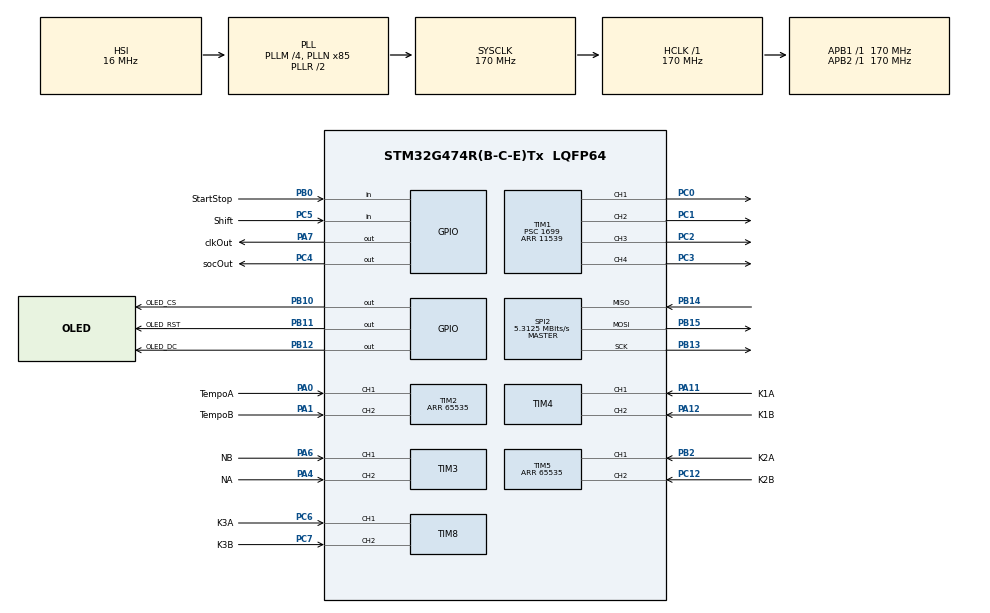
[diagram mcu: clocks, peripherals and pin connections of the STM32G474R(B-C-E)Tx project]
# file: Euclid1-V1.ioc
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Mcu.Family=STM32G4
Mcu.Name=STM32G474R(B-C-E)Tx
Mcu.Package=LQFP64
NUCLEO-G474RE.VCP=true
NVIC.PriorityGroup=NVIC_PRIORITYGROUP_4
NVIC.TIM1_TRG_COM_TIM17_IRQn=true\:1\:0\:true\:false\:true\:true\:true\:true
NVIC.TIM1_UP_TIM16_IRQn=true\:0\:0\:false\:false\:true\:true\:true\:true
PA0.GPIO_Label=TempoA
PA0.GPIO_PuPd=GPIO_PULLUP
PA0.Signal=S_TIM2_CH1
PA1.GPIO_Label=TempoB
PA1.GPIO_PuPd=GPIO_PULLUP
PA1.Signal=S_TIM2_CH2
PA11.GPIO_Label=K1A
PA11.GPIO_PuPd=GPIO_PULLUP
PA11.Signal=S_TIM4_CH1
PA12.GPIO_Label=K1B
PA12.GPIO_PuPd=GPIO_PULLUP
PA12.Signal=S_TIM4_CH2
PA13.GPIO_Label=T_SWDIO
PA13.Mode=Serial_Wire
PA13.Signal=SYS_JTMS-SWDIO
PA14.GPIO_Label=T_SWCLK
PA14.Mode=Serial_Wire
PA14.Signal=SYS_JTCK-SWCLK
PA2.Signal=LPUART1_TX
PA3.Signal=LPUART1_RX
PA4.GPIO_Label=NA
PA4.GPIO_PuPd=GPIO_PULLUP
PA4.Signal=S_TIM3_CH2
PA6.GPIO_Label=NB
PA6.GPIO_PuPd=GPIO_PULLUP
PA6.Signal=S_TIM3_CH1
PA7.GPIO_Label=clkOut
PA7.Signal=GPIO_Output
PB0.GPIO_Label=StartStop
PB0.GPIO_PuPd=GPIO_PULLUP
PB0.Signal=GPIO_Input
PB10.GPIO_Label=OLED_CS
PB10.PinState=GPIO_PIN_SET
PB10.Signal=GPIO_Output
PB11.GPIO_Label=OLED_RST
PB11.Signal=GPIO_Output
PB12.GPIO_Label=OLED_DC
PB12.Signal=GPIO_Output
PB13.Mode=Full_Duplex_Master
PB13.Signal=SPI2_SCK
PB14.Mode=Full_Duplex_Master
PB14.Signal=SPI2_MISO
PB15.Mode=Full_Duplex_Master
PB15.Signal=SPI2_MOSI
PB2.GPIO_Label=K2A
PB2.GPIO_PuPd=GPIO_PULLUP
PB2.Signal=S_TIM5_CH1
PB3.GPIO_Label=T_SWO
PB3.Signal=SYS_JTDO-SWO
PC0.Signal=S_TIM1_CH1
PC1.Signal=S_TIM1_CH2
PC12.GPIO_Label=K2B
PC12.GPIO_PuPd=GPIO_PULLUP
PC12.Signal=S_TIM5_CH2
PC14-OSC32_IN.GPIO_Label=RCC_OSC32_IN
PC14-OSC32_IN.Signal=RCC_OSC32_IN
PC15-OSC32_OUT.GPIO_Label=RCC_OSC32_OUT
PC15-OSC32_OUT.Signal=RCC_OSC32_OUT
PC2.Signal=S_TIM1_CH3
PC3.Signal=S_TIM1_CH4
PC4.GPIO_Label=socOut
PC4.GPIO_PuPd=GPIO_NOPULL
PC4.Signal=GPIO_Output
PC5.GPIO_Label=Shift
PC5.GPIO_PuPd=GPIO_PULLUP
PC5.Signal=GPIO_Input
PC6.GPIO_Label=K3A
PC6.GPIO_PuPd=GPIO_PULLUP
PC6.Signal=S_TIM8_CH1
PC7.GPIO_Label=K3B
PC7.GPIO_PuPd=GPIO_PULLUP
PC7.Signal=S_TIM8_CH2
PF0-OSC_IN.GPIO_Label=RCC_OSC_IN
PF0-OSC_IN.Signal=RCC_OSC_IN
PF1-OSC_OUT.GPIO_Label=RCC_OSC_OUT
PF1-OSC_OUT.Signal=RCC_OSC_OUT
ProjectManager.HeapSize=0x200
ProjectManager.StackSize=0x400
ProjectManager.TargetToolchain=STM32CubeIDE
RCC.ADC12Freq_Value=170000000
RCC.ADC345Freq_Value=170000000
RCC.AHBFreq_Value=170000000
RCC.APB1Freq_Value=170000000
RCC.APB1TimFreq_Value=170000000
RCC.APB2Freq_Value=170000000
RCC.APB2TimFreq_Value=170000000
RCC.CortexFreq_Value=170000000
RCC.EXTERNAL_CLOCK_VALUE=12288000
RCC.HCLKFreq_Value=170000000
RCC.HSE_VALUE=24000000
RCC.HSI48_VALUE=48000000
RCC.HSI_VALUE=16000000
RCC.LSE_VALUE=32768
RCC.PLLM=RCC_PLLM_DIV4
RCC.PLLN=85
RCC.RTCClockSelection=RCC_RTCCLKSOURCE_LSE
RCC.SYSCLKFreq_VALUE=170000000
RCC.SYSCLKSource=RCC_SYSCLKSOURCE_PLLCLK
RCC.USBFreq_Value=170000000
RCC.VCOOutputFreq_Value=340000000
SH.S_TIM1_CH1.0=TIM1_CH1,PWM Generation1 CH1
SH.S_TIM1_CH2.0=TIM1_CH2,PWM Generation2 CH2
SH.S_TIM1_CH3.0=TIM1_CH3,PWM Generation3 CH3
SH.S_TIM1_CH4.0=TIM1_CH4,PWM Generation4 CH4
SH.S_TIM2_CH1.0=TIM2_CH1,Encoder_Interface
SH.S_TIM2_CH2.0=TIM2_CH2,Encoder_Interface
SH.S_TIM3_CH1.0=TIM3_CH1,Encoder_Interface
SH.S_TIM3_CH2.0=TIM3_CH2,Encoder_Interface
SH.S_TIM4_CH1.0=TIM4_CH1,Encoder_Interface
SH.S_TIM4_CH2.0=TIM4_CH2,Encoder_Interface
SH.S_TIM5_CH1.0=TIM5_CH1,Encoder_Interface
SH.S_TIM5_CH2.0=TIM5_CH2,Encoder_Interface
SH.S_TIM8_CH1.0=TIM8_CH1,Encoder_Interface
SH.S_TIM8_CH2.0=TIM8_CH2,Encoder_Interface
SPI2.BaudRatePrescaler=SPI_BAUDRATEPRESCALER_32
SPI2.CalculateBaudRate=5.3125 MBits/s
SPI2.DataSize=SPI_DATASIZE_8BIT
SPI2.Direction=SPI_DIRECTION_2LINES
SPI2.Mode=SPI_MODE_MASTER
SPI2.VirtualType=VM_MASTER
TIM1.AutoReloadPreload=TIM_AUTORELOAD_PRELOAD_ENABLE
TIM1.Channel-PWM\ Generation1\ CH1=TIM_CHANNEL_1
TIM1.Channel-PWM\ Generation2\ CH2=TIM_CHANNEL_2
TIM1.Channel-PWM\ Generation3\ CH3=TIM_CHANNEL_3
TIM1.Channel-PWM\ Generation4\ CH4=TIM_CHANNEL_4
TIM1.PeriodNoDither=11539
TIM1.Prescaler=1699
TIM1.TIM_MasterOutputTrigger=TIM_TRGO_UPDATE
TIM17.PeriodNoDither=11539
TIM17.Prescaler=1699
TIM2.EncoderMode=TIM_ENCODERMODE_TI12
TIM2.IC1Filter=8
TIM2.IC2Filter=8
TIM2.PeriodNoDither=65535
TIM3.EncoderMode=TIM_ENCODERMODE_TI12
TIM3.IC1Filter=8
TIM3.IC2Filter=8
TIM4.EncoderMode=TIM_ENCODERMODE_TI12
TIM4.IC1Filter=8
TIM4.IC2Filter=8
TIM5.EncoderMode=TIM_ENCODERMODE_TI12
TIM5.IC1Filter=8
TIM5.IC2Filter=8
TIM5.PeriodNoDither=65535
TIM8.EncoderMode=TIM_ENCODERMODE_TI12
TIM8.IC1Filter=8
TIM8.IC2Filter=8
VP_NUCLEO-G474RE_VS_BSP_COMMON.Mode=COMMON
VP_SYS_VS_DBSignals.Mode=DisableDeadBatterySignals
VP_TIM17_VS_ClockSourceINT.Mode=Enable_Timer
VP_TIM17_VS_OPM.Mode=OPM_bit
board=NUCLEO-G474RE

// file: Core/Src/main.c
/* USER CODE BEGIN Header */
/**
  ******************************************************************************
  * @file           : main.c
  * @brief          : Main program body
  ******************************************************************************
  * @attention
  *
  * Copyright (c) 2026 STMicroelectronics.
  * All rights reserved.
  *
  * This software is licensed under terms that can be found in the LICENSE file
  * in the root directory of this software component.
  * If no LICENSE file comes with this software, it is provided AS-IS.
  *
  ******************************************************************************
  */
/* USER CODE END Header */
#include "main.h"

/* USER CODE BEGIN Includes */
#include "app.h"
/* USER CODE END Includes */

COM_InitTypeDef BspCOMInit;
SPI_HandleTypeDef hspi2;

TIM_HandleTypeDef htim1;
TIM_HandleTypeDef htim2;
TIM_HandleTypeDef htim3;
TIM_HandleTypeDef htim4;
TIM_HandleTypeDef htim5;
TIM_HandleTypeDef htim8;
TIM_HandleTypeDef htim17;

void SystemClock_Config(void);
static void MX_GPIO_Init(void);
static void MX_TIM1_Init(void);
static void MX_TIM2_Init(void);
static void MX_TIM3_Init(void);
static void MX_TIM4_Init(void);
static void MX_TIM5_Init(void);
static void MX_TIM8_Init(void);
static void MX_TIM17_Init(void);
static void MX_SPI2_Init(void);

int main(void)
{

  /* MCU Configuration--------------------------------------------------------*/

  /* Reset of all peripherals, Initializes the Flash interface and the Systick. */
  HAL_Init();

  /* Configure the system clock */
  SystemClock_Config();

  /* Initialize all configured peripherals */
  MX_GPIO_Init();
  MX_TIM1_Init();
  MX_TIM2_Init();
  MX_TIM3_Init();
  MX_TIM4_Init();
  MX_TIM5_Init();
  MX_TIM8_Init();
  MX_TIM17_Init();
  MX_SPI2_Init();

  /* Initialize COM1 port (115200, 8 bits (7-bit data + 1 stop bit), no parity */
  BspCOMInit.BaudRate   = 115200;
  BspCOMInit.WordLength = COM_WORDLENGTH_8B;
  BspCOMInit.StopBits   = COM_STOPBITS_1;
  BspCOMInit.Parity     = COM_PARITY_NONE;
  BspCOMInit.HwFlowCtl  = COM_HWCONTROL_NONE;
  if (BSP_COM_Init(COM1, &BspCOMInit) != BSP_ERROR_NONE)
  {
    Error_Handler();
  }

  /* Infinite loop */
  /* USER CODE BEGIN WHILE */
  /* Must be here, not in USER CODE 2: BSP_COM_Init() above configures LPUART1,
     and app_init() prints its banner through it. */
  app_init();

  while (1)
  {

    /* USER CODE END WHILE */

    /* USER CODE BEGIN 3 */
    app_tick();
  }
  /* USER CODE END 3 */
}

void SystemClock_Config(void)
{
  RCC_OscInitTypeDef RCC_OscInitStruct = {0};
  RCC_ClkInitTypeDef RCC_ClkInitStruct = {0};

  /** Configure the main internal regulator output voltage
  */
  HAL_PWREx_ControlVoltageScaling(PWR_REGULATOR_VOLTAGE_SCALE1_BOOST);

  /** Initializes the RCC Oscillators according to the specified parameters
  * in the RCC_OscInitTypeDef structure.
  */
  RCC_OscInitStruct.OscillatorType = RCC_OSCILLATORTYPE_HSI;
  RCC_OscInitStruct.HSIState = RCC_HSI_ON;
  RCC_OscInitStruct.HSICalibrationValue = RCC_HSICALIBRATION_DEFAULT;
  RCC_OscInitStruct.PLL.PLLState = RCC_PLL_ON;
  RCC_OscInitStruct.PLL.PLLSource = RCC_PLLSOURCE_HSI;
  RCC_OscInitStruct.PLL.PLLM = RCC_PLLM_DIV4;
  RCC_OscInitStruct.PLL.PLLN = 85;
  RCC_OscInitStruct.PLL.PLLP = RCC_PLLP_DIV2;
  RCC_OscInitStruct.PLL.PLLQ = RCC_PLLQ_DIV2;
  RCC_OscInitStruct.PLL.PLLR = RCC_PLLR_DIV2;
  if (HAL_RCC_OscConfig(&RCC_OscInitStruct) != HAL_OK)
  {
    Error_Handler();
  }

  /** Initializes the CPU, AHB and APB buses clocks
  */
  RCC_ClkInitStruct.ClockType = RCC_CLOCKTYPE_HCLK|RCC_CLOCKTYPE_SYSCLK
                              |RCC_CLOCKTYPE_PCLK1|RCC_CLOCKTYPE_PCLK2;
  RCC_ClkInitStruct.SYSCLKSource = RCC_SYSCLKSOURCE_PLLCLK;
  RCC_ClkInitStruct.AHBCLKDivider = RCC_SYSCLK_DIV1;
  RCC_ClkInitStruct.APB1CLKDivider = RCC_HCLK_DIV1;
  RCC_ClkInitStruct.APB2CLKDivider = RCC_HCLK_DIV1;

  if (HAL_RCC_ClockConfig(&RCC_ClkInitStruct, FLASH_LATENCY_4) != HAL_OK)
  {
    Error_Handler();
  }
}

static void MX_SPI2_Init(void)
{

  /* SPI2 parameter configuration*/
  hspi2.Instance = SPI2;
  hspi2.Init.Mode = SPI_MODE_MASTER;
  hspi2.Init.Direction = SPI_DIRECTION_2LINES;
  hspi2.Init.DataSize = SPI_DATASIZE_8BIT;
  hspi2.Init.CLKPolarity = SPI_POLARITY_LOW;
  hspi2.Init.CLKPhase = SPI_PHASE_1EDGE;
  hspi2.Init.NSS = SPI_NSS_SOFT;
  hspi2.Init.BaudRatePrescaler = SPI_BAUDRATEPRESCALER_32;
  hspi2.Init.FirstBit = SPI_FIRSTBIT_MSB;
  hspi2.Init.TIMode = SPI_TIMODE_DISABLE;
  hspi2.Init.CRCCalculation = SPI_CRCCALCULATION_DISABLE;
  hspi2.Init.CRCPolynomial = 7;
  hspi2.Init.CRCLength = SPI_CRC_LENGTH_DATASIZE;
  hspi2.Init.NSSPMode = SPI_NSS_PULSE_ENABLE;
  if (HAL_SPI_Init(&hspi2) != HAL_OK)
  {
    Error_Handler();
  }

}

static void MX_TIM1_Init(void)
{

  TIM_MasterConfigTypeDef sMasterConfig = {0};
  TIM_OC_InitTypeDef sConfigOC = {0};
  TIM_BreakDeadTimeConfigTypeDef sBreakDeadTimeConfig = {0};

  htim1.Instance = TIM1;
  htim1.Init.Prescaler = 1699;
  htim1.Init.CounterMode = TIM_COUNTERMODE_UP;
  htim1.Init.Period = 11539;
  htim1.Init.ClockDivision = TIM_CLOCKDIVISION_DIV1;
  htim1.Init.RepetitionCounter = 0;
  htim1.Init.AutoReloadPreload = TIM_AUTORELOAD_PRELOAD_ENABLE;
  if (HAL_TIM_PWM_Init(&htim1) != HAL_OK)
  {
    Error_Handler();
  }
  sMasterConfig.MasterOutputTrigger = TIM_TRGO_UPDATE;
  sMasterConfig.MasterOutputTrigger2 = TIM_TRGO2_RESET;
  sMasterConfig.MasterSlaveMode = TIM_MASTERSLAVEMODE_DISABLE;
  if (HAL_TIMEx_MasterConfigSynchronization(&htim1, &sMasterConfig) != HAL_OK)
  {
    Error_Handler();
  }
  sConfigOC.OCMode = TIM_OCMODE_PWM1;
  sConfigOC.Pulse = 0;
  sConfigOC.OCPolarity = TIM_OCPOLARITY_HIGH;
  sConfigOC.OCNPolarity = TIM_OCNPOLARITY_HIGH;
  sConfigOC.OCFastMode = TIM_OCFAST_DISABLE;
  sConfigOC.OCIdleState = TIM_OCIDLESTATE_RESET;
  sConfigOC.OCNIdleState = TIM_OCNIDLESTATE_RESET;
  if (HAL_TIM_PWM_ConfigChannel(&htim1, &sConfigOC, TIM_CHANNEL_1) != HAL_OK)
  {
    Error_Handler();
  }
  if (HAL_TIM_PWM_ConfigChannel(&htim1, &sConfigOC, TIM_CHANNEL_2) != HAL_OK)
  {
    Error_Handler();
  }
  if (HAL_TIM_PWM_ConfigChannel(&htim1, &sConfigOC, TIM_CHANNEL_3) != HAL_OK)
  {
    Error_Handler();
  }
  if (HAL_TIM_PWM_ConfigChannel(&htim1, &sConfigOC, TIM_CHANNEL_4) != HAL_OK)
  {
    Error_Handler();
  }
  sBreakDeadTimeConfig.OffStateRunMode = TIM_OSSR_DISABLE;
  sBreakDeadTimeConfig.OffStateIDLEMode = TIM_OSSI_DISABLE;
  sBreakDeadTimeConfig.LockLevel = TIM_LOCKLEVEL_OFF;
  sBreakDeadTimeConfig.DeadTime = 0;
  sBreakDeadTimeConfig.BreakState = TIM_BREAK_DISABLE;
  sBreakDeadTimeConfig.BreakPolarity = TIM_BREAKPOLARITY_HIGH;
  sBreakDeadTimeConfig.BreakFilter = 0;
  sBreakDeadTimeConfig.BreakAFMode = TIM_BREAK_AFMODE_INPUT;
  sBreakDeadTimeConfig.Break2State = TIM_BREAK2_DISABLE;
  sBreakDeadTimeConfig.Break2Polarity = TIM_BREAK2POLARITY_HIGH;
  sBreakDeadTimeConfig.Break2Filter = 0;
  sBreakDeadTimeConfig.Break2AFMode = TIM_BREAK_AFMODE_INPUT;
  sBreakDeadTimeConfig.AutomaticOutput = TIM_AUTOMATICOUTPUT_DISABLE;
  if (HAL_TIMEx_ConfigBreakDeadTime(&htim1, &sBreakDeadTimeConfig) != HAL_OK)
  {
    Error_Handler();
  }
  HAL_TIM_MspPostInit(&htim1);

}

static void MX_TIM2_Init(void)
{

  TIM_Encoder_InitTypeDef sConfig = {0};
  TIM_MasterConfigTypeDef sMasterConfig = {0};

  htim2.Instance = TIM2;
  htim2.Init.Prescaler = 0;
  htim2.Init.CounterMode = TIM_COUNTERMODE_UP;
  htim2.Init.Period = 65535;
  htim2.Init.ClockDivision = TIM_CLOCKDIVISION_DIV1;
  htim2.Init.AutoReloadPreload = TIM_AUTORELOAD_PRELOAD_DISABLE;
  sConfig.EncoderMode = TIM_ENCODERMODE_TI12;
  sConfig.IC1Polarity = TIM_ICPOLARITY_RISING;
  sConfig.IC1Selection = TIM_ICSELECTION_DIRECTTI;
  sConfig.IC1Prescaler = TIM_ICPSC_DIV1;
  sConfig.IC1Filter = 8;
  sConfig.IC2Polarity = TIM_ICPOLARITY_RISING;
  sConfig.IC2Selection = TIM_ICSELECTION_DIRECTTI;
  sConfig.IC2Prescaler = TIM_ICPSC_DIV1;
  sConfig.IC2Filter = 8;
  if (HAL_TIM_Encoder_Init(&htim2, &sConfig) != HAL_OK)
  {
    Error_Handler();
  }
  sMasterConfig.MasterOutputTrigger = TIM_TRGO_RESET;
  sMasterConfig.MasterSlaveMode = TIM_MASTERSLAVEMODE_DISABLE;
  if (HAL_TIMEx_MasterConfigSynchronization(&htim2, &sMasterConfig) != HAL_OK)
  {
    Error_Handler();
  }

}

static void MX_TIM3_Init(void)
{

  TIM_Encoder_InitTypeDef sConfig = {0};
  TIM_MasterConfigTypeDef sMasterConfig = {0};

  htim3.Instance = TIM3;
  htim3.Init.Prescaler = 0;
  htim3.Init.CounterMode = TIM_COUNTERMODE_UP;
  htim3.Init.Period = 65535;
  htim3.Init.ClockDivision = TIM_CLOCKDIVISION_DIV1;
  htim3.Init.AutoReloadPreload = TIM_AUTORELOAD_PRELOAD_DISABLE;
  sConfig.EncoderMode = TIM_ENCODERMODE_TI12;
  sConfig.IC1Polarity = TIM_ICPOLARITY_RISING;
  sConfig.IC1Selection = TIM_ICSELECTION_DIRECTTI;
  sConfig.IC1Prescaler = TIM_ICPSC_DIV1;
  sConfig.IC1Filter = 8;
  sConfig.IC2Polarity = TIM_ICPOLARITY_RISING;
  sConfig.IC2Selection = TIM_ICSELECTION_DIRECTTI;
  sConfig.IC2Prescaler = TIM_ICPSC_DIV1;
  sConfig.IC2Filter = 8;
  if (HAL_TIM_Encoder_Init(&htim3, &sConfig) != HAL_OK)
  {
    Error_Handler();
  }
  sMasterConfig.MasterOutputTrigger = TIM_TRGO_RESET;
  sMasterConfig.MasterSlaveMode = TIM_MASTERSLAVEMODE_DISABLE;
  if (HAL_TIMEx_MasterConfigSynchronization(&htim3, &sMasterConfig) != HAL_OK)
  {
    Error_Handler();
  }

}

static void MX_TIM4_Init(void)
{

  TIM_Encoder_InitTypeDef sConfig = {0};
  TIM_MasterConfigTypeDef sMasterConfig = {0};

  htim4.Instance = TIM4;
  htim4.Init.Prescaler = 0;
  htim4.Init.CounterMode = TIM_COUNTERMODE_UP;
  htim4.Init.Period = 65535;
  htim4.Init.ClockDivision = TIM_CLOCKDIVISION_DIV1;
  htim4.Init.AutoReloadPreload = TIM_AUTORELOAD_PRELOAD_DISABLE;
  sConfig.EncoderMode = TIM_ENCODERMODE_TI12;
  sConfig.IC1Polarity = TIM_ICPOLARITY_RISING;
  sConfig.IC1Selection = TIM_ICSELECTION_DIRECTTI;
  sConfig.IC1Prescaler = TIM_ICPSC_DIV1;
  sConfig.IC1Filter = 8;
  sConfig.IC2Polarity = TIM_ICPOLARITY_RISING;
  sConfig.IC2Selection = TIM_ICSELECTION_DIRECTTI;
  sConfig.IC2Prescaler = TIM_ICPSC_DIV1;
  sConfig.IC2Filter = 8;
  if (HAL_TIM_Encoder_Init(&htim4, &sConfig) != HAL_OK)
  {
    Error_Handler();
  }
  sMasterConfig.MasterOutputTrigger = TIM_TRGO_RESET;
  sMasterConfig.MasterSlaveMode = TIM_MASTERSLAVEMODE_DISABLE;
  if (HAL_TIMEx_MasterConfigSynchronization(&htim4, &sMasterConfig) != HAL_OK)
  {
    Error_Handler();
  }

}

static void MX_TIM5_Init(void)
{

  TIM_Encoder_InitTypeDef sConfig = {0};
  TIM_MasterConfigTypeDef sMasterConfig = {0};

  htim5.Instance = TIM5;
  htim5.Init.Prescaler = 0;
  htim5.Init.CounterMode = TIM_COUNTERMODE_UP;
  htim5.Init.Period = 65535;
  htim5.Init.ClockDivision = TIM_CLOCKDIVISION_DIV1;
  htim5.Init.AutoReloadPreload = TIM_AUTORELOAD_PRELOAD_DISABLE;
  sConfig.EncoderMode = TIM_ENCODERMODE_TI12;
  sConfig.IC1Polarity = TIM_ICPOLARITY_RISING;
  sConfig.IC1Selection = TIM_ICSELECTION_DIRECTTI;
  sConfig.IC1Prescaler = TIM_ICPSC_DIV1;
  sConfig.IC1Filter = 8;
  sConfig.IC2Polarity = TIM_ICPOLARITY_RISING;
  sConfig.IC2Selection = TIM_ICSELECTION_DIRECTTI;
  sConfig.IC2Prescaler = TIM_ICPSC_DIV1;
  sConfig.IC2Filter = 8;
  if (HAL_TIM_Encoder_Init(&htim5, &sConfig) != HAL_OK)
  {
    Error_Handler();
  }
  sMasterConfig.MasterOutputTrigger = TIM_TRGO_RESET;
  sMasterConfig.MasterSlaveMode = TIM_MASTERSLAVEMODE_DISABLE;
  if (HAL_TIMEx_MasterConfigSynchronization(&htim5, &sMasterConfig) != HAL_OK)
  {
    Error_Handler();
  }

}

static void MX_TIM8_Init(void)
{

  TIM_Encoder_InitTypeDef sConfig = {0};
  TIM_MasterConfigTypeDef sMasterConfig = {0};

  htim8.Instance = TIM8;
  htim8.Init.Prescaler = 0;
  htim8.Init.CounterMode = TIM_COUNTERMODE_UP;
  htim8.Init.Period = 65535;
  htim8.Init.ClockDivision = TIM_CLOCKDIVISION_DIV1;
  htim8.Init.RepetitionCounter = 0;
  htim8.Init.AutoReloadPreload = TIM_AUTORELOAD_PRELOAD_DISABLE;
  sConfig.EncoderMode = TIM_ENCODERMODE_TI12;
  sConfig.IC1Polarity = TIM_ICPOLARITY_RISING;
  sConfig.IC1Selection = TIM_ICSELECTION_DIRECTTI;
  sConfig.IC1Prescaler = TIM_ICPSC_DIV1;
  sConfig.IC1Filter = 8;
  sConfig.IC2Polarity = TIM_ICPOLARITY_RISING;
  sConfig.IC2Selection = TIM_ICSELECTION_DIRECTTI;
  sConfig.IC2Prescaler = TIM_ICPSC_DIV1;
  sConfig.IC2Filter = 8;
  if (HAL_TIM_Encoder_Init(&htim8, &sConfig) != HAL_OK)
  {
    Error_Handler();
  }
  sMasterConfig.MasterOutputTrigger = TIM_TRGO_RESET;
  sMasterConfig.MasterOutputTrigger2 = TIM_TRGO2_RESET;
  sMasterConfig.MasterSlaveMode = TIM_MASTERSLAVEMODE_DISABLE;
  if (HAL_TIMEx_MasterConfigSynchronization(&htim8, &sMasterConfig) != HAL_OK)
  {
    Error_Handler();
  }

}

static void MX_TIM17_Init(void)
{

  htim17.Instance = TIM17;
  htim17.Init.Prescaler = 1699;
  htim17.Init.CounterMode = TIM_COUNTERMODE_UP;
  htim17.Init.Period = 11539;
  htim17.Init.ClockDivision = TIM_CLOCKDIVISION_DIV1;
  htim17.Init.RepetitionCounter = 0;
  htim17.Init.AutoReloadPreload = TIM_AUTORELOAD_PRELOAD_DISABLE;
  if (HAL_TIM_Base_Init(&htim17) != HAL_OK)
  {
    Error_Handler();
  }
  if (HAL_TIM_OnePulse_Init(&htim17, TIM_OPMODE_SINGLE) != HAL_OK)
  {
    Error_Handler();
  }

}

static void MX_GPIO_Init(void)
{
  GPIO_InitTypeDef GPIO_InitStruct = {0};

  /* GPIO Ports Clock Enable */
  __HAL_RCC_GPIOC_CLK_ENABLE();
  __HAL_RCC_GPIOF_CLK_ENABLE();
  __HAL_RCC_GPIOA_CLK_ENABLE();
  __HAL_RCC_GPIOB_CLK_ENABLE();

  /*Configure GPIO pin Output Level */
  HAL_GPIO_WritePin(clkOut_GPIO_Port, clkOut_Pin, GPIO_PIN_RESET);

  /*Configure GPIO pin Output Level */
  HAL_GPIO_WritePin(socOut_GPIO_Port, socOut_Pin, GPIO_PIN_RESET);

  /*Configure GPIO pin Output Level */
  HAL_GPIO_WritePin(OLED_CS_GPIO_Port, OLED_CS_Pin, GPIO_PIN_SET);

  /*Configure GPIO pin Output Level */
  HAL_GPIO_WritePin(GPIOB, OLED_RST_Pin|OLED_DC_Pin, GPIO_PIN_RESET);

  /*Configure GPIO pins : PA2 PA3 */
  GPIO_InitStruct.Pin = GPIO_PIN_2|GPIO_PIN_3;
  GPIO_InitStruct.Mode = GPIO_MODE_AF_PP;
  GPIO_InitStruct.Pull = GPIO_NOPULL;
  GPIO_InitStruct.Speed = GPIO_SPEED_FREQ_LOW;
  GPIO_InitStruct.Alternate = GPIO_AF12_LPUART1;
  HAL_GPIO_Init(GPIOA, &GPIO_InitStruct);

  /*Configure GPIO pin : clkOut_Pin */
  GPIO_InitStruct.Pin = clkOut_Pin;
  GPIO_InitStruct.Mode = GPIO_MODE_OUTPUT_PP;
  GPIO_InitStruct.Pull = GPIO_NOPULL;
  GPIO_InitStruct.Speed = GPIO_SPEED_FREQ_LOW;
  HAL_GPIO_Init(clkOut_GPIO_Port, &GPIO_InitStruct);

  /*Configure GPIO pin : socOut_Pin */
  GPIO_InitStruct.Pin = socOut_Pin;
  GPIO_InitStruct.Mode = GPIO_MODE_OUTPUT_PP;
  GPIO_InitStruct.Pull = GPIO_NOPULL;
  GPIO_InitStruct.Speed = GPIO_SPEED_FREQ_LOW;
  HAL_GPIO_Init(socOut_GPIO_Port, &GPIO_InitStruct);

  /*Configure GPIO pin : Shift_Pin */
  GPIO_InitStruct.Pin = Shift_Pin;
  GPIO_InitStruct.Mode = GPIO_MODE_INPUT;
  GPIO_InitStruct.Pull = GPIO_PULLUP;
  HAL_GPIO_Init(Shift_GPIO_Port, &GPIO_InitStruct);

  /*Configure GPIO pin : StartStop_Pin */
  GPIO_InitStruct.Pin = StartStop_Pin;
  GPIO_InitStruct.Mode = GPIO_MODE_INPUT;
  GPIO_InitStruct.Pull = GPIO_PULLUP;
  HAL_GPIO_Init(StartStop_GPIO_Port, &GPIO_InitStruct);

  /*Configure GPIO pins : OLED_CS_Pin OLED_RST_Pin OLED_DC_Pin */
  GPIO_InitStruct.Pin = OLED_CS_Pin|OLED_RST_Pin|OLED_DC_Pin;
  GPIO_InitStruct.Mode = GPIO_MODE_OUTPUT_PP;
  GPIO_InitStruct.Pull = GPIO_NOPULL;
  GPIO_InitStruct.Speed = GPIO_SPEED_FREQ_LOW;
  HAL_GPIO_Init(GPIOB, &GPIO_InitStruct);

}

void Error_Handler(void)
{
  __disable_irq();
  while (1)
  {
  }
}
